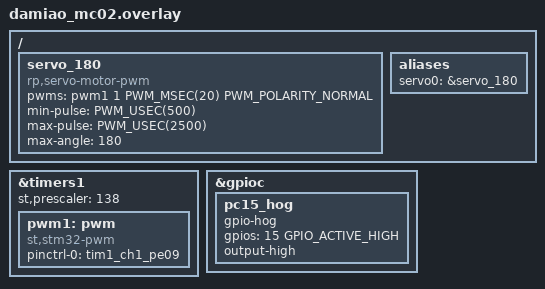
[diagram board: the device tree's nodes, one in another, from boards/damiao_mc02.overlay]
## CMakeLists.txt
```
# Copyright (c) 2025 RobotPilots-SZU
# SPDX-License-Identifier: Apache-2.0

cmake_minimum_required(VERSION 3.20)

# check BOARD variable
if(NOT BOARD)
    set(BOARD damiao_mc02)
    message("BOARD not defined, use default value: ${BOARD}")
else()
    message("Use BOARD: ${BOARD}")
endif()

# import zephyr library
find_package(Zephyr REQUIRED HINTS $ENV{ZEPHYR_BASE})

# define cmake project
project(servo-motor-pwm)

target_sources(app PRIVATE
    ./src/main.cpp
)
```

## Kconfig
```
# Copyright (c) 2025 RobotPilots-SZU
# SPDX-License-Identifier: Apache-2.0

source "Kconfig.zephyr"
source "../../breeze/drivers/servo_motor_pwm/Kconfig"
```

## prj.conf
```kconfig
CONFIG_ASSERT=y
CONFIG_SERVO_MOTOR_PWM=y
CONFIG_SERVO_INIT_PRIORITY=92
CONFIG_SERVO_MOTOR_PWM_LOG_LEVEL=4
CONFIG_GPIO=y		//喵板 PWM 5V供电需要使能，C板可忽略此项

CONFIG_PRINTK=y
CONFIG_USE_SEGGER_RTT=y
CONFIG_CONSOLE=y
CONFIG_RTT_CONSOLE=y
CONFIG_UART_CONSOLE=n

CONFIG_LOG=y
CONFIG_LOG_PROCESS_THREAD_STACK_SIZE=4096
CONFIG_LOG_BACKEND_RTT=y

# 保留基本优化但便于调试
CONFIG_DEBUG_OPTIMIZATIONS=y     //如果不配置这一条可能导致代码被优化掉，断点无效
```

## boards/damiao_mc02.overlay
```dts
/*
 * Copyright (c) 2025 RobotPilots-SZU
 * SPDX-License-Identifier: Apache-2.0
 */

/* This file will automatic applyed when using damiao_mc02 board */

&timers1 {
    status = "okay";
    st,prescaler = <138>;    // 137.5MHz / 137.5 = 1MHz

    pwm1: pwm{
        compatible = "st,stm32-pwm";
        status = "okay";
        pinctrl-0 = <&tim1_ch1_pe09>;
        pinctrl-names = "default";
    };
};

&gpioc {
    pc15_hog {
        gpio-hog;
        gpios = <15 GPIO_ACTIVE_HIGH>;	//使能喵板PWM 5V
        output-high;
    };
};

/ {
    servo_180: servo_180 {
        compatible = "rp,servo-motor-pwm";
        pwms = <&pwm1 1 PWM_MSEC(20) PWM_POLARITY_NORMAL>;  // use tim1_ch1_pe09
        min-pulse = <PWM_USEC(500)>;
        max-pulse = <PWM_USEC(2500)>;
        max-angle = <180>;
    };

    // servo_270: servo_270 {
    //     compatible = "rp,servo-motor-pwm";
    //     pwms = <&pwm1 1 PWM_MSEC(20) PWM_POLARITY_NORMAL>;  // use tim1_ch1_pe09
    //     min-pulse = <PWM_USEC(500)>;
    //     max-pulse = <PWM_USEC(2500)>;
    //     max-angle = <270>;
    // };

    // servo_300: servo_300 {
    //     compatible = "rp,servo-motor-pwm";
    //     pwms = <&pwm1 1 PWM_MSEC(20) PWM_POLARITY_NORMAL>;  // use tim1_ch1_pe09
    //     min-pulse = <PWM_USEC(500)>;
    //     max-pulse = <PWM_USEC(2500)>;
    //     max-angle = <300>;
    // };
};

/ {
    aliases {
        servo0 = &servo_180;
        // servo1 = &servo_270;
        // servo2 = &servo_300;
    };
};
```

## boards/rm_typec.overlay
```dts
/*
 * Copyright (c) 2025 RobotPilots-SZU
 * SPDX-License-Identifier: Apache-2.0
 */

/* This file will automatic applyed when using rm_typec board */

&timers8 {
    st,prescaler = <167>; // 1 MHz timer clock
    status = "okay";
    pwm8: pwm {
        status = "okay";
        pinctrl-0 = <&tim8_ch1_pc6>;
        pinctrl-names = "default";
    };
};

/ {
    servo_180: servo_180 {
        compatible = "rp,servo-motor-pwm";
        pwms = <&pwm8 1 PWM_MSEC(20) PWM_POLARITY_NORMAL>;  // use tim8_ch1_pc6
        min-pulse = <PWM_USEC(500)>;
        max-pulse = <PWM_USEC(2500)>;
        max-angle = <180>;
    };

    // servo_270: servo_270 {
    //     compatible = "rp,servo-motor-pwm";
    //     pwms = <&pwm8 1 PWM_MSEC(20) PWM_POLARITY_NORMAL>;  // use tim8_ch1_pc6
    //     min-pulse = <PWM_USEC(500)>;
    //     max-pulse = <PWM_USEC(2500)>;
    //     max-angle = <270>;
    // };

    // servo_300: servo_300 {
    //     compatible = "rp,servo-motor-pwm";
    //     pwms = <&pwm8 1 PWM_MSEC(20) PWM_POLARITY_NORMAL>;  // use tim8_ch1_pc6
    //     min-pulse = <PWM_USEC(500)>;
    //     max-pulse = <PWM_USEC(2500)>;
    //     max-angle = <300>;
    // };
};

/ {
    aliases {
        servo0 = &servo_180;
        // servo1 = &servo_270;
        // servo2 = &servo_300;
    };
};
```

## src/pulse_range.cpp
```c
// #include <zephyr/kernel.h>
// #include <zephyr/device.h>
// #include <zephyr/devicetree.h>
// #include <zephyr/sys/printk.h>
// #include <zephyr/drivers/pwm.h>
// #include <zephyr/logging/log.h>
// #include <drivers/servo_motor_pwm.h>

// /* 
// *   日志模块注册
// *   改成LOG_LEVEL_DBG即可输出DBG级别的日志
// *   输出DBG级别日志需要注意 CONFIG_LOG_PROCESS_THREAD_STACK_SIZE 配置，防止日志过多导致栈溢出
// */
// LOG_MODULE_REGISTER(servo_motor, LOG_LEVEL_INF);

// static const struct device *servo = DEVICE_DT_GET(DT_ALIAS(servo0));
// static const struct pwm_dt_spec servo_pwm = PWM_DT_SPEC_GET(DT_ALIAS(servo0));

// int main(void)
// {
// 	if (!device_is_ready(servo_pwm.dev)) {
// 		LOG_ERR("Servo PWM device is not ready");
// 		return 0;
// 	}

// 	if (servo_set_mechanical_limit_angle(servo, 180.0f, 0.0f) != 0) {
// 		LOG_ERR("Failed to set mechanical limits, %s", servo->name);
// 		return 0;
// 	}

// 	if (servo_set_offset_angle(servo, 0.0f) != 0) {
// 		LOG_ERR("Failed to set offset, %s", servo->name);
// 		return 0;
// 	}

// 	/* Get PWM controller/channel/period from the servo node pwms property. */
// 	while (1) 
// 	{
// 		int ret;
// 		for (int pulse = 100000; pulse <= 550000; pulse += 10000) {
// 			ret = pwm_set_pulse_dt(&servo_pwm, pulse);
// 			LOG_INF("set pulse %d ns, ret=%d", pulse, ret);
// 			k_msleep(1000);
// 		}

// 		for (int pulse = 3000000; pulse >= 2400000; pulse -= 10000) {
// 			ret = pwm_set_pulse_dt(&servo_pwm, pulse);
// 			LOG_INF("set pulse %d ns, ret=%d", pulse, ret);
// 			k_msleep(1000);
// 		}
// 	}

// 	return 0;
// }
```
